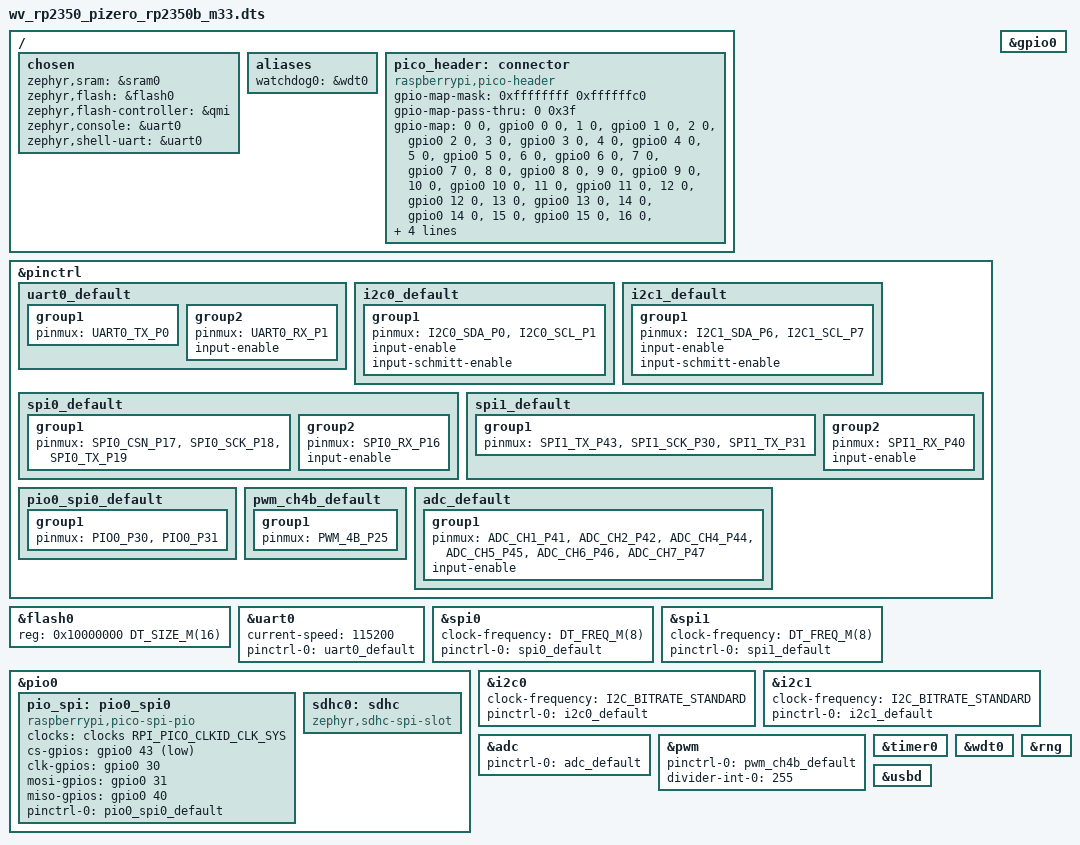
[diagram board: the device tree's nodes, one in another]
/*
 * Copyright (c) 2024 Andrew Featherstone
 * Copyright (c) 2024 Fabien Georget
 *
 * SPDX-License-Identifier: Apache-2.0
 */

/dts-v1/;

#include <raspberrypi/rpi_pico/rp2350b.dtsi>
#include <raspberrypi/rpi_pico/m33.dtsi>

#include <freq.h>

#include <zephyr/dt-bindings/i2c/i2c.h>
#include <zephyr/dt-bindings/pwm/pwm.h>
#include <zephyr/dt-bindings/pinctrl/rpi-pico-rp2350b-pinctrl.h>

&pinctrl {
	uart0_default: uart0_default {
		group1 {
			pinmux = <UART0_TX_P0>;
		};

		group2 {
			pinmux = <UART0_RX_P1>;
			input-enable;
		};
	};

	i2c0_default: i2c0_default {
		group1 {
			pinmux = <I2C0_SDA_P0>, <I2C0_SCL_P1>;
			input-enable;
			input-schmitt-enable;
		};
	};

	i2c1_default: i2c1_default {
		group1 {
			pinmux = <I2C1_SDA_P6>, <I2C1_SCL_P7>;
			input-enable;
			input-schmitt-enable;
		};
	};

	spi0_default: spi0_default {
		group1 {
			pinmux = <SPI0_CSN_P17>, <SPI0_SCK_P18>, <SPI0_TX_P19>;
		};

		group2 {
			pinmux = <SPI0_RX_P16>;
			input-enable;
		};
	};

	spi1_default: spi1_default {
		group1 {
			pinmux = <SPI1_TX_P43>, <SPI1_SCK_P30>, <SPI1_TX_P31>;
		};

		group2 {
			pinmux = <SPI1_RX_P40>;
			input-enable;
		};
	};

	pio0_spi0_default: pio0_spi0_default {
	/* gpio 10 is used for chip select, not assigned to the PIO */
		group1 {
			pinmux = <PIO0_P30>, <PIO0_P31>;
		};
	};

	pwm_ch4b_default: pwm_ch4b_default {
		group1 {
			pinmux = <PWM_4B_P25>;
		};
	};

	adc_default: adc_default {
		group1 {
			pinmux = <ADC_CH1_P41>, <ADC_CH2_P42>, <ADC_CH4_P44>, <ADC_CH5_P45>, <ADC_CH6_P46>, <ADC_CH7_P47>;
			input-enable;
		};
	};
};


/ {
	chosen {
		zephyr,sram = &sram0;
		zephyr,flash = &flash0;
		zephyr,flash-controller = &qmi;
		zephyr,console = &uart0;
		zephyr,shell-uart = &uart0;
	};

	aliases {
		watchdog0 = &wdt0;
	};

	pico_header: connector {
		compatible = "raspberrypi,pico-header";
		#gpio-cells = <2>;
		gpio-map-mask = <0xffffffff 0xffffffc0>;
		gpio-map-pass-thru = <0 0x3f>;
		gpio-map = <0 0 &gpio0 0 0>,	/* GP0 */
			   <1 0 &gpio0 1 0>,	/* GP1 */
			   <2 0 &gpio0 2 0>,	/* GP2 */
			   <3 0 &gpio0 3 0>,	/* GP3 */
			   <4 0 &gpio0 4 0>,	/* GP4 */
			   <5 0 &gpio0 5 0>,	/* GP5 */
			   <6 0 &gpio0 6 0>,	/* GP6 */
			   <7 0 &gpio0 7 0>,	/* GP7 */
			   <8 0 &gpio0 8 0>,	/* GP8 */
			   <9 0 &gpio0 9 0>,	/* GP9 */
			   <10 0 &gpio0 10 0>,	/* GP10 */
			   <11 0 &gpio0 11 0>,	/* GP11 */
			   <12 0 &gpio0 12 0>,	/* GP12 */
			   <13 0 &gpio0 13 0>,	/* GP13 */
			   <14 0 &gpio0 14 0>,	/* GP14 */
			   <15 0 &gpio0 15 0>,	/* GP15 */
			   <16 0 &gpio0 16 0>,	/* GP16 */
			   <17 0 &gpio0 17 0>,	/* GP17 */
			   <18 0 &gpio0 18 0>,	/* GP18 */
			   <19 0 &gpio0 19 0>,	/* GP19 */
			   <20 0 &gpio0 20 0>,	/* GP20 */
			   <21 0 &gpio0 21 0>,	/* GP21 */
			   <22 0 &gpio0 22 0>,	/* GP22 */
			   <26 0 &gpio0 26 0>;	/* GP26 */
	};
};

&flash0 {
	reg = <0x10000000 DT_SIZE_M(16)>;
};

&uart0 {
	current-speed = <115200>;
	status = "okay";
	pinctrl-0 = <&uart0_default>;
	pinctrl-names = "default";
};

gpio0_lo: &gpio0 {
	status = "okay";
};

&spi0 {
	clock-frequency = <DT_FREQ_M(8)>;
	pinctrl-0 = <&spi0_default>;
	pinctrl-names = "default";
};

&pio0 {
	status = "okay";

	pio_spi: pio0_spi0 {
		compatible = "raspberrypi,pico-spi-pio";
		clocks = <&clocks RPI_PICO_CLKID_CLK_SYS>;
		#address-cells = <1>;
		#size-cells = <0>;
		cs-gpios = <&gpio0 43 GPIO_ACTIVE_LOW>;
		clk-gpios = <&gpio0 30 GPIO_ACTIVE_HIGH>;
		mosi-gpios = <&gpio0 31 GPIO_ACTIVE_HIGH>;
		miso-gpios = <&gpio0 40 GPIO_ACTIVE_HIGH>;
		pinctrl-0 = <&pio0_spi0_default>;
		pinctrl-names = "default";
	};

	sdhc0: sdhc {
		compatible = "zephyr,sdhc-spi-slot";
	};
};


&spi1 {
	clock-frequency = <DT_FREQ_M(8)>;
	pinctrl-0 = <&spi1_default>;
	pinctrl-names = "default";

	//cs-gpios = <&gpio0 43 GPIO_ACTIVE_LOW>;

	//clk-gpios = <&gpio0 30 GPIO_ACTIVE_HIGH>;
	//mosi-gpios = <&gpio0 31 GPIO_ACTIVE_HIGH>;
	//miso-gpios = <&gpio0 40 GPIO_ACTIVE_HIGH>;

};

&i2c0 {
	clock-frequency = <I2C_BITRATE_STANDARD>;
	pinctrl-0 = <&i2c0_default>;
	pinctrl-names = "default";
};

&i2c1 {
	clock-frequency = <I2C_BITRATE_STANDARD>;
	pinctrl-0 = <&i2c1_default>;
	pinctrl-names = "default";
};

&adc {
	pinctrl-0 = <&adc_default>;
	pinctrl-names = "default";
};

&pwm {
	pinctrl-0 = <&pwm_ch4b_default>;
	pinctrl-names = "default";
	divider-int-0 = <255>;
};

&timer0 {
	status = "okay";
};

&wdt0 {
	status = "okay";
};

&rng {
	status = "okay";
};

zephyr_udc0: &usbd {
	status = "okay";
};

pico_spi: &spi0 {};

pico_spi0: &spi0 {};

pico_i2c: &i2c0 {};

pico_i2c0: &i2c0 {};

pico_i2c1: &i2c1 {};

pico_serial: &uart0 {};

pico_serial0: &uart0 {};


